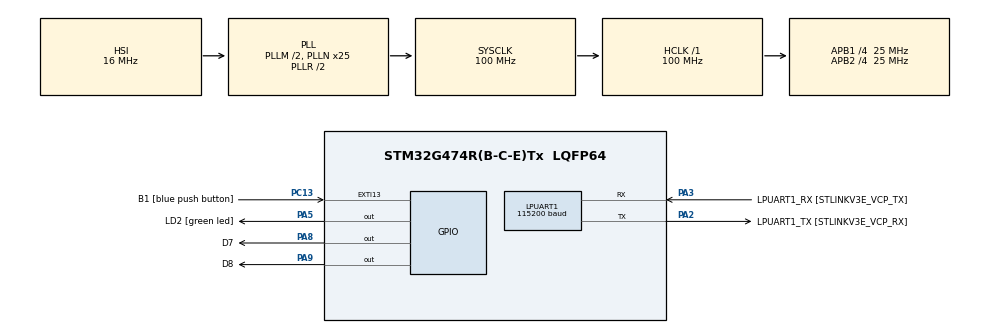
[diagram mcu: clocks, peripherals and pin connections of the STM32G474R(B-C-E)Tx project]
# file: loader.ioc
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LPUART1.BaudRate=115200
LPUART1.WordLength=UART_WORDLENGTH_8B
Mcu.Family=STM32G4
Mcu.Name=STM32G474R(B-C-E)Tx
Mcu.Package=LQFP64
NVIC.EXTI15_10_IRQn=true\:0\:0\:false\:false\:true\:true\:true\:true
NVIC.PriorityGroup=NVIC_PRIORITYGROUP_4
PA13.GPIO_Label=T_SWDIO
PA13.Mode=Serial_Wire
PA13.Signal=SYS_JTMS-SWDIO
PA14.GPIO_Label=T_SWCLK
PA14.Mode=Serial_Wire
PA14.Signal=SYS_JTCK-SWCLK
PA2.GPIO_Label=LPUART1_TX [STLINKV3E_VCP_RX]
PA2.Mode=Asynchronous
PA2.Signal=LPUART1_TX
PA3.GPIO_Label=LPUART1_RX [STLINKV3E_VCP_TX]
PA3.Mode=Asynchronous
PA3.Signal=LPUART1_RX
PA5.GPIO_Label=LD2 [green led]
PA5.Signal=GPIO_Output
PA8.GPIO_Label=D7
PA8.GPIO_Speed=GPIO_SPEED_FREQ_HIGH
PA8.Signal=GPIO_Output
PA9.GPIO_Label=D8
PA9.GPIO_Speed=GPIO_SPEED_FREQ_HIGH
PA9.Signal=GPIO_Output
PB3.GPIO_Label=T_SWO
PB3.Signal=SYS_JTDO-SWO
PC13.GPIO_Label=B1 [blue push button]
PC13.GPIO_ModeDefaultEXTI=GPIO_MODE_IT_RISING
PC13.Signal=GPXTI13
PC14-OSC32_IN.Mode=LSE-External-Oscillator
PC14-OSC32_IN.Signal=RCC_OSC32_IN
PC15-OSC32_OUT.Mode=LSE-External-Oscillator
PC15-OSC32_OUT.Signal=RCC_OSC32_OUT
PF0-OSC_IN.Mode=HSE-External-Oscillator
PF0-OSC_IN.Signal=RCC_OSC_IN
PF1-OSC_OUT.Mode=HSE-External-Oscillator
PF1-OSC_OUT.Signal=RCC_OSC_OUT
ProjectManager.HeapSize=0x200
ProjectManager.StackSize=0x400
ProjectManager.TargetToolchain=STM32CubeIDE
RCC.ADC12Freq_Value=100000000
RCC.ADC345Freq_Value=100000000
RCC.AHBFreq_Value=100000000
RCC.APB1CLKDivider=RCC_HCLK_DIV4
RCC.APB1Freq_Value=25000000
RCC.APB1TimFreq_Value=50000000
RCC.APB2CLKDivider=RCC_HCLK_DIV4
RCC.APB2Freq_Value=25000000
RCC.APB2TimFreq_Value=50000000
RCC.CortexFreq_Value=100000000
RCC.EXTERNAL_CLOCK_VALUE=12288000
RCC.HCLKFreq_Value=100000000
RCC.HSE_VALUE=24000000
RCC.HSI48_VALUE=48000000
RCC.HSI_VALUE=16000000
RCC.PLLM=RCC_PLLM_DIV2
RCC.PLLN=25
RCC.RTCClockSelection=RCC_RTCCLKSOURCE_LSE
RCC.SYSCLKFreq_VALUE=100000000
RCC.SYSCLKSource=RCC_SYSCLKSOURCE_PLLCLK
RCC.USBFreq_Value=100000000
RCC.VCOOutputFreq_Value=200000000
VP_SYS_VS_DBSignals.Mode=DisableDeadBatterySignals
board=NUCLEO-G474RE

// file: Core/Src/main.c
/* USER CODE BEGIN Header */
/**
  ******************************************************************************
  * @file           : main.c
  * @brief          : Main program body
  ******************************************************************************
  * @attention
  *
  * Copyright (c) 2024 STMicroelectronics.
  * All rights reserved.
  *
  * This software is licensed under terms that can be found in the LICENSE file
  * in the root directory of this software component.
  * If no LICENSE file comes with this software, it is provided AS-IS.
  *
  ******************************************************************************
  */
/* USER CODE END Header */
#include "main.h"
#include "usart.h"
#include "gpio.h"

/* USER CODE BEGIN Includes */
#include "com_task.h"
/* USER CODE END Includes */

void SystemClock_Config(void);

int main(void)
{
  /* USER CODE BEGIN 1 */
	uint32_t last_time;
	uint32_t elapse;

  /* USER CODE END 1 */

  /* MCU Configuration--------------------------------------------------------*/

  /* Reset of all peripherals, Initializes the Flash interface and the Systick. */
  HAL_Init();

  /* Configure the system clock */
  SystemClock_Config();

  /* Initialize all configured peripherals */
  MX_GPIO_Init();
  MX_LPUART1_UART_Init();
  /* USER CODE BEGIN 2 */
  last_time = HAL_GetTick();
  COM_Initialize();
  /* USER CODE END 2 */

  /* Infinite loop */
  /* USER CODE BEGIN WHILE */
  while (1)
  {
		elapse = HAL_GetTick() - last_time;
		if (elapse > 1000)
		{
			last_time = HAL_GetTick();
			HAL_GPIO_TogglePin(LD2_GPIO_Port, LD2_Pin);
		}

		COM_Task();

		if (HAL_GPIO_ReadPin(B1_GPIO_Port, B1_Pin) == GPIO_PIN_SET)
		{
			COM_BT_JumpToApp();
		}

    /* USER CODE END WHILE */

  }
}

void SystemClock_Config(void)
{
  RCC_OscInitTypeDef RCC_OscInitStruct = {0};
  RCC_ClkInitTypeDef RCC_ClkInitStruct = {0};

  /** Configure the main internal regulator output voltage
  */
  HAL_PWREx_ControlVoltageScaling(PWR_REGULATOR_VOLTAGE_SCALE1);

  /** Initializes the RCC Oscillators according to the specified parameters
  * in the RCC_OscInitTypeDef structure.
  */
  RCC_OscInitStruct.OscillatorType = RCC_OSCILLATORTYPE_HSI;
  RCC_OscInitStruct.HSIState = RCC_HSI_ON;
  RCC_OscInitStruct.HSICalibrationValue = RCC_HSICALIBRATION_DEFAULT;
  RCC_OscInitStruct.PLL.PLLState = RCC_PLL_ON;
  RCC_OscInitStruct.PLL.PLLSource = RCC_PLLSOURCE_HSI;
  RCC_OscInitStruct.PLL.PLLM = RCC_PLLM_DIV2;
  RCC_OscInitStruct.PLL.PLLN = 25;
  RCC_OscInitStruct.PLL.PLLP = RCC_PLLP_DIV2;
  RCC_OscInitStruct.PLL.PLLQ = RCC_PLLQ_DIV2;
  RCC_OscInitStruct.PLL.PLLR = RCC_PLLR_DIV2;
  if (HAL_RCC_OscConfig(&RCC_OscInitStruct) != HAL_OK)
  {
    Error_Handler();
  }

  /** Initializes the CPU, AHB and APB buses clocks
  */
  RCC_ClkInitStruct.ClockType = RCC_CLOCKTYPE_HCLK|RCC_CLOCKTYPE_SYSCLK
                              |RCC_CLOCKTYPE_PCLK1|RCC_CLOCKTYPE_PCLK2;
  RCC_ClkInitStruct.SYSCLKSource = RCC_SYSCLKSOURCE_PLLCLK;
  RCC_ClkInitStruct.AHBCLKDivider = RCC_SYSCLK_DIV1;
  RCC_ClkInitStruct.APB1CLKDivider = RCC_HCLK_DIV4;
  RCC_ClkInitStruct.APB2CLKDivider = RCC_HCLK_DIV4;

  if (HAL_RCC_ClockConfig(&RCC_ClkInitStruct, FLASH_LATENCY_3) != HAL_OK)
  {
    Error_Handler();
  }
}

/* USER CODE BEGIN 4 */

/* External interrupt: Blue button */
void HAL_GPIO_EXTI_Callback(uint16_t GPIO_Pin)
{
	if (GPIO_Pin != B1_Pin) { return; }

	// your code here
}
/* USER CODE END 4 */

void Error_Handler(void)
{
  __disable_irq();
  while (1)
  {
  }
}
